# STM32N657xx register map
File version: 1.0
Registers are 32-bit, read-write, reset 0x0 unless marked. A register's access mark holds for its fields unless they carry their own. Offsets are from the block's base; [hi:lo] are bit positions; 'fields as' and 'values as' point back to an identical list; <NAME> marks a mode.

## LTDC — LCD-TFT Display Controller (LTDC)
Base 0x48001000
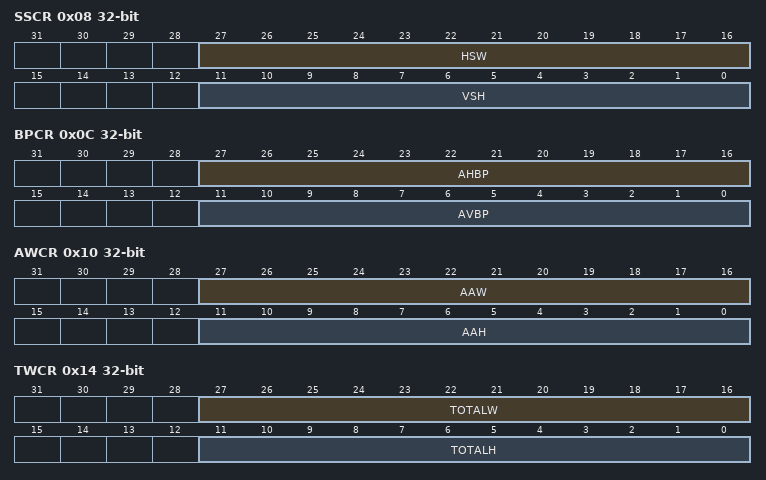
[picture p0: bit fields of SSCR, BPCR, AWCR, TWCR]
0x08 SSCR — LTDC synchronization size configuration register
  [27:16] HSW — horizontal synchronization width (in units of pixel clock period)These bits define the number of Horizontal Synchronization pixel minus 1
  [11:0] VSH — vertical synchronization height (in units of horizontal scan line)These bits define the vertical Synchronization height minus 1. It represents the number of horizontal synchronization lines
0x0C BPCR — LTDC back porch configuration register
  [27:16] AHBP — accumulated horizontal back porch (in units of pixel clock period)These bits define the accumulated horizontal back porch width that includes the horizontal synchronization and horizontal back porch pixels minus 1.The horizontal back porch is the period between horizontal synchronization going inactive and the start of the active display part of the next scan line
  [11:0] AVBP — accumulated Vertical back porch (in units of horizontal scan line)These bits define the accumulated vertical back porch width that includes the vertical synchronization and vertical back porch lines minus 1.The vertical back porch is the number of horizontal scan lines at a start of frame to the start of the first active scan line of the next frame
0x10 AWCR — LTDC active width configuration register
  [27:16] AAW — accumulated active width (in units of pixel clock period)These bits define the accumulated active width which includes the horizontal synchronization, horizontal back porch and active pixels minus 1.The active width is the number of pixels in active display area of the panel scan line.Refer to device datasheet for maximum active width supported following maximum pixel clock
  [11:0] AAH — accumulated active height (in units of horizontal scan line)These bits define the accumulated height which includes the vertical synchronization, vertical back porch and the active height lines minus 1. The active height is the number of active lines in the panel.Refer to device datasheet for maximum active height supported following maximum pixel clock
0x14 TWCR — LTDC total width configuration register
  [27:16] TOTALW — total width (in units of pixel clock period)These bits defines the accumulated total width which includes the horizontal synchronization, horizontal back porch, active width and horizontal front porch pixels minus 1
  [11:0] TOTALH — total height (in units of horizontal scan line)These bits defines the accumulated height which includes the vertical synchronization, vertical back porch, the active height and vertical front porch height lines minus 1
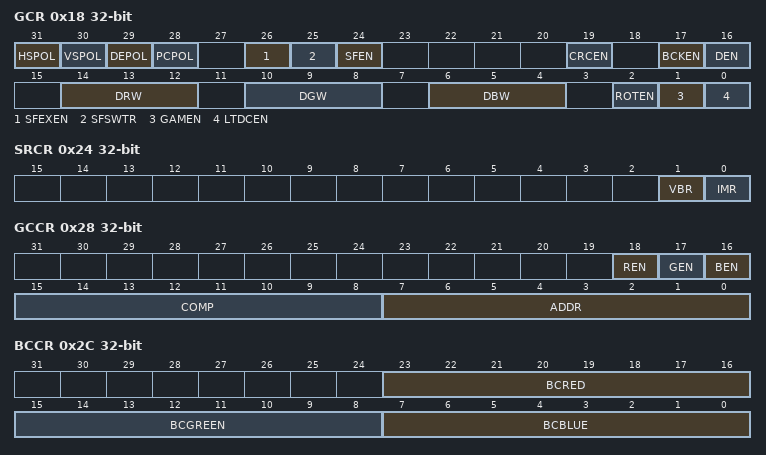
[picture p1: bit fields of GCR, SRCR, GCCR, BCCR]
0x18 GCR — LTDC global control register
  [31] HSPOL — horizontal synchronization polarityThis bit is set and cleared by software.- 0: horizontal synchronization polarity is active low.- 1: horizontal synchronization polarity is active high
  [30] VSPOL — vertical synchronization polarityThis bit is set and cleared by software.- 0: vertical synchronization is active low.- 1: vertical synchronization is active high
  [29] DEPOL — blanking (=no data/pixel) polarityThis bit is set and cleared by software.- 0: blanking (no data/pixel) polarity is active low.- 1: blanking (no data/pixel) polarity is active high
  [28] PCPOL — pixel clock polarityThis bit is set and cleared by software.- 0: pixel clock polarity is active low.- 1: pixel clock is active high
  [26] SFEXEN — single-frame mode: external trigger enableThis bit is set and cleared by software.- 0: external trigger disable- 1: external trigger enable: a trigger on the external trigger will generate one single frame
  [25] SFSWTR — single-frame mode: software triggerThis bit is set by software and cleared by hardware.- 0: no action- 1: triggers one frame
  [24] SFEN — single-frame mode: mode enableThis bit is set and cleared by software.- 0: single-frame disable:a trigger (on SFSW or External) will generate a continuous flow.- 1: single-frame enable: a trigger (on SFSW or External) will generate a single frame
  [19] CRCEN — CRC enableThis bit is set and cleared by software.- 0: CRC disable- 1: CRC enable
  [17] BCKEN — backgroundlayer enableThis bit is set and cleared by software.- 0: backgrounddisable- 1: background enable
  [16] DEN — dither enableThis bit is set and cleared by software.- 0: dither disable- 1: dither enable
  [14:12] DRW — dither red widthThese bits return the Dither Red Bits
  [10:8] DGW — dither green widthThese bits return the dither green bits
  [6:4] DBW — dither blue widthThese bits return the dither blue bits
  [2] ROTEN — LCD-TFT controller enableThis bit is set and cleared by software.- 0: Rotation disable- 1: Rotation enable (for a pure visual rotation, the mirroring has to be activated)
  [1] GAMEN — LCD-TFT controller enableThis bit is set and cleared by software.- 0: GammaCorrection disable (pixels bypass the gamma operator)- 1: Gamma Correction enable
  [0] LTDCEN — LCD-TFT controller enableThis bit is set and cleared by software.- 0: LTDC disable- 1: LTDC enable
0x24 SRCR — LTDC shadow reload configuration register
  [1] VBR — vertical blanking reload requestThis bit is set by software and cleared only by hardware after reload (it cannot be cleared through register write once it is set).- 0: no effect- 1: The shadow registers are reloaded during the vertical blanking period (at the beginning of the first line after the active display area)
  [0] IMR — immediate reload triggerThis bit is set by software and cleared only by hardware after reload.- 0: no effect- 1: The shadow registers are reloaded immediately
0x28 GCCR — LTDC gamma correction configuration register
  [18] REN — write trigger to the red table- 0: no action done- 1: COMP is written at ADDR in the Red table
  [17] GEN — write trigger to the green table- 0: no action done- 1: COMP is written at ADDR in the Green table
  [16] BEN — write trigger to the blue table- 0: no action done- 1: COMP is written at ADDR in the Blue table
  [15:8] COMP — color component to be written, in either (or all) the R,G,B tables
  [7:0] ADDR — address of the R,G,B table where the COMP component is written.When LTDC_GC1R.GCT=2, the gamma is implemented with 8 interpolated segment. In that case, the valid ADDR addresses are: 0, 32, 64, 96, 128, 160, 192, 224, 255.Note that for ADDR=255, the gamma interpolation hardware considers that the address is 256
0x2C BCCR — LTDC background color configuration register
  [23:16] BCRED — background color red valueThese bits configure the background red value
  [15:8] BCGREEN — background color green valueThese bits configure the background green value
  [7:0] BCBLUE — background color blue valueThese bits configure the background blue value
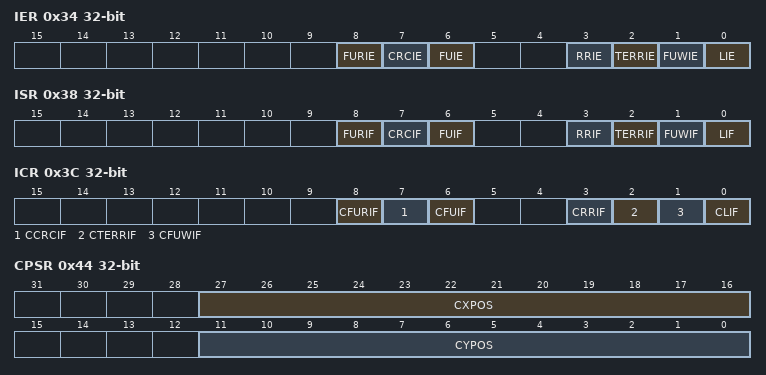
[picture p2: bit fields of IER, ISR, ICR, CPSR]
0x34 IER — LTDC interrupt enable register
  [8] FURIE — FIFOunderrun at rotation interrupt enableThis bit is set and cleared by software.- 0: FIFOunderrun at rotation interrupt disable- 1: FIFO underrunat rotation interrupt enable
  [7] CRCIE — CRC error interrupt enableThis bit is set and cleared by software.- 0: crcerror disable- 1: crc error interrupt enable
  [6] FUIE — FIFO underrun interrupt enableThis bit is set and cleared by software.- 0: FIFO underrun killing interrupt disable- 1: FIFO underrun killing Interrupt enable
  [3] RRIE — register reload interrupt enableThis bit is set and cleared by software.- 0: register reload interrupt disable- 1: register reload interrupt enable
  [2] TERRIE — transfer error interrupt enableThis bit is set and cleared by software.- 0: transfer error interrupt disable- 1: transfer error interrupt enable
  [1] FUWIE — FIFO underrun warning interrupt enableThis bit is set and cleared by software.- 0: FIFO underrun interrupt disable- 1: FIFO underrun Interrupt enable
  [0] LIE — line interrupt enableThis bit is set and cleared by software.- 0: line interrupt disable- 1: line interrupt enable
0x38 ISR — LTDC interrupt status register
  [8] FURIF — FIFO underrun at rotation interrupt flag- 0: no FIFO underrun at rotation interrupt generated- 1: FIFO underrun at rotation interrupt generated
  [7] CRCIF — transfer error interrupt flag- 0: no CRC error interrupt generated- 1: CRC error interrupt generated when the computed CRC is different from the expected CRC
  [6] FUIF — FIFO underrun interrupt flag- 0: no FIFO underrun killing interrupt generated.- 1: FIFO underrun killing interrupt generated, if one of the layer FIFOs is empty and many pixel data is read from the FIFO
  [3] RRIF — register reload interrupt flag- 0: no register reload interrupt generated- 1: register reload interrupt generated when a vertical blanking reload occurs (and the first line after the active area is reached)
  [2] TERRIF — transfer error interrupt flag- 0: no transfer error interrupt generated- 1: transfer error interrupt generated when a bus error occurs
  [1] FUWIF — FIFO underrun warning interrupt flag- 0: no FIFO underrun warning interrupt generated.- 1: FIFO underrun warning interrupt generated, if one of the layer FIFOs is empty and pixel data is read from the FIFO
  [0] LIF — line interrupt flag- 0: no line interrupt generated- 1: line interrupt generated when a programmed line is reached
0x3C ICR — LTDC Interrupt Clear Register
  [8] CFURIF — clears register reload interrupt flag- 0: no effect- 1: clears the FURIF flag in the LTDC_ISR register
  [7] CCRCIF — clears the transfer error interrupt flag- 0: no effect- 1: clears the CRCIF flag in the LTDC_ISR register
  [6] CFUIF — clears the FIFO underrun warning interrupt flag- 0: no effect- 1: clears the FUKIF flag in the LTDC_ISR register
  [3] CRRIF — clears register reload interrupt flag- 0: no effect- 1: clears the RRIF flag in the LTDC_ISR register
  [2] CTERRIF — clears the transfer error interrupt flag- 0: no effect- 1: clears the TERRIF flag in the LTDC_ISR register
  [1] CFUWIF — clears the FIFO underrun warning interrupt flag- 0: no effect- 1: clears the FUWIF flag in the LTDC_ISR register
  [0] CLIF — clears the line interrupt flag- 0: no effect- 1: clears the LIF flag in the LTDC_ISR register
0x40 LIPCR — LTDC line interrupt position configuration register
  [11:0] LIPOS — line interrupt positionThese bits configure the line interrupt position
0x44 CPSR — LTDC current position status register
  [27:16] CXPOS — current X positionThese bits return the current X position
  [11:0] CYPOS — current Y positionThese bits return the current Y position
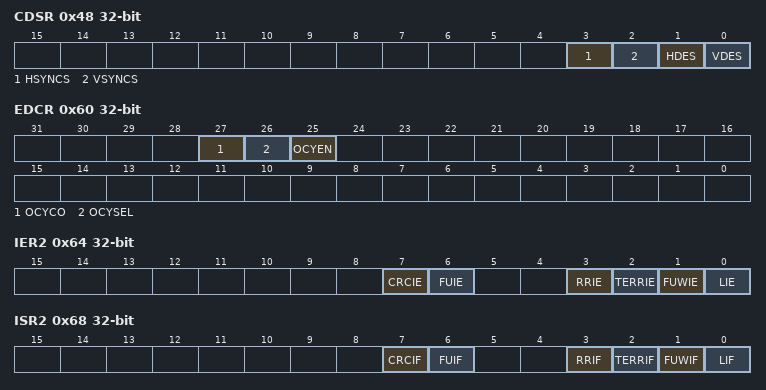
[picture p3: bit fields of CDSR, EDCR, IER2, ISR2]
0x48 CDSR — LTDC current display status register
  [3] HSYNCS — horizontal synchronization display status- 0: active low- 1: active high
  [2] VSYNCS — vertical synchronization display status- 0: active low- 1: active high
  [1] HDES — horizontal data enable display status- 0: active low- 1: active high
  [0] VDES — vertical data enable display status- 0: active low- 1: active high
0x60 EDCR — LTDC external display control register
  [27] OCYCO — output conversion to YCbCr 422: chrominance order.- 0: Cb is output first (so: Y0Cb, then Y1Cr, Y2Cb, etc .. ).- 1: Cr is output first (so: Y0Cr, then Y1Cb, Y2Cr, etc ..)
  [26] OCYSEL — output conversion to YCbCr 422: selection of the CCIR hard-wired coefficients:- 0: use CCIR-BT601 set (for typically SDTV analog-like displays)- 1: use CCIR-BT709 set (for typically HDTV digital-like displays)
  [25] OCYEN — output conversion to YCbCr 422: Enable- 0: conversion is disabled- 1: conversion is enabled
0x64 IER2 — LTDC interrupt enable register 2
  [7] CRCIE — CRC error interrupt enableThis bit is set and cleared by software.- 0: crcerror disable- 1: crc error interrupt enable
  [6] FUIE — FIFO underrun interrupt enableThis bit is set and cleared by software.- 0: FIFO underrun killing interrupt disable- 1: FIFO underrun killing Interrupt enable
  [3] RRIE — register reload interrupt enableThis bit is set and cleared by software.- 0: register reload interrupt disable- 1: register reload interrupt enable
  [2] TERRIE — transfer error interrupt enableThis bit is set and cleared by software.- 0: transfer error interrupt disable- 1: transfer error interrupt enable
  [1] FUWIE — FIFO underrun warning interrupt enableThis bit is set and cleared by software.- 0: FIFO underrun interrupt disable- 1: FIFO underrun Interrupt enable
  [0] LIE — line interrupt enableThis bit is set and cleared by software.- 0: line interrupt disable- 1: line interrupt enable
0x68 ISR2 — LTDC interrupt status register 2
  [7] CRCIF — transfer error interrupt flag- 0: no CRC error interrupt generated- 1: CRC error interrupt generated when a bus error occurs
  [6] FUIF — FIFO underrun interrupt flag- 0: no FIFO underrun killing interrupt generated.- 1: FIFO underrun killing interrupt generated, if one of the layer FIFOs is empty and many pixel data are read from the FIFO
  [3] RRIF — register reload interrupt flag- 0: no register reload interrupt generated- 1: register reload interrupt generated when a vertical blanking reload occurs (and the first line after the active area is reached)
  [2] TERRIF — transfer error interrupt flag- 0: no transfer error interrupt generated- 1: transfer error interrupt generated when a bus error occurs
  [1] FUWIF — FIFO underrun warning interrupt flag- 0: no FIFO underrun warning interrupt generated.- 1: FIFO underrun warning interrupt generated, if one of the layer FIFOs is empty and pixel data is read from the FIFO
  [0] LIF — line interrupt flag- 0: no line interrupt generated- 1: line interrupt generated when a programmed line is reached
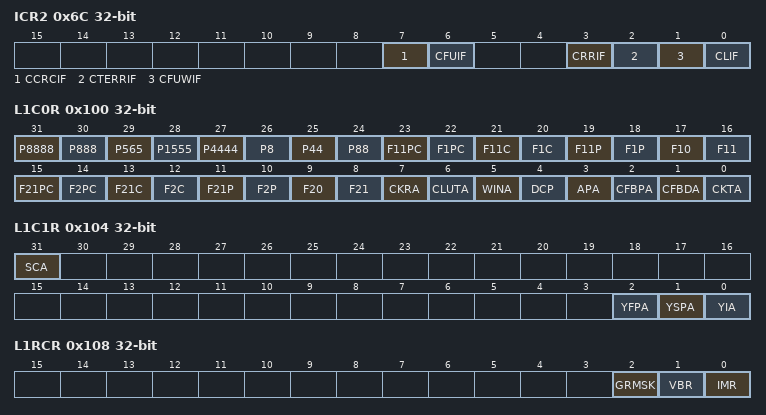
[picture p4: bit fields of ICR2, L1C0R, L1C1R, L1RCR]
0x6C ICR2 — LTDC Interrupt Clear Register 2
  [7] CCRCIF — clears the transfer error interrupt flag- 0: no effect- 1: clears the CRCIF flag in the LTDC_ISR register
  [6] CFUIF — clears the FIFO underrun warning interrupt flag- 0: no effect- 1: clears the FUKIF flag in the LTDC_ISR register
  [3] CRRIF — clears register reload interrupt flag- 0: no effect- 1: clears the RRIF flag in the LTDC_ISR register
  [2] CTERRIF — clears the transfer error interrupt flag- 0: no effect- 1: clears the TERRIF flag in the LTDC_ISR register
  [1] CFUWIF — clears the FIFO underrun warning interrupt flag- 0: no effect- 1: clears the FUWIF flag in the LTDC_ISR register
  [0] CLIF — clears the line interrupt flag- 0: no effect- 1: clears the LIF flag in the LTDC_ISR register
0x70 LIPCR2 — LTDC line interrupt position configuration register 2
  [15:0] LIPOS — line interrupt positionThese bits configure the line interrupt position
0x78 ECRCR — LTDC expected CRC register
  [15:0] ECRC — expected CRC of frame
0x7C CCRCR — LTDC computed CRC register
  [15:0] CCRC — expected CRC of frame
0x80 RB0AR — LTDC rotation buffer 0 address register
0x84 RB1AR — LTDC rotation buffer 1 address register
0x88 RBPR — LTDC rotation buffer pitch register
0x8C RIFCR — LTDC rotation intermediate frame color register
0x90 FUTR — LTDC FIFO underrun threshold register
  [15:0] THRE — threshold to trigger a FIFO underrun killing interrupt (unit is per fifo word, 64bit)
0x100 L1C0R — LTDC layer x configuration 0 register
  [31] P8888 — pixel format, ability for: ARGB8888
  [30] P888 — pixel format, ability for: RGB888
  [29] P565 — pixel format, ability for: RGB565
  [28] P1555 — pixel format, ability for: ARGB1555
  [27] P4444 — pixel format, ability for: ARGB4444
  [26] P8 — pixel format, ability for: L8
  [25] P44 — pixel format, ability for: AL44
  [24] P88 — pixel format, ability for: AL88
  [23] F11PC — blending factor 1, ability for: 1.0 - (pixel_alpha constant_alpha)
  [22] F1PC — blending factor 1, ability for: pixel_alpha constant_alpha
  [21] F11C — blending factor 1, ability for: 1.0 - constant_alpha
  [20] F1C — blending factor 1, ability for: constant_alpha
  [19] F11P — blending factor 1, ability for: 1.0 - pixel_alpha
  [18] F1P — blending factor 1, ability for: pixel_alpha
  [17] F10 — blending factor 1,ability for: 0.0
  [16] F11 — blending factor 1, ability for: 1.0
  [15] F21PC — blending factor 2, ability for: 1.0 - (pixel_alpha constant_alpha)
  [14] F2PC — blending factor 2, ability for: pixel_alpha constant_alpha
  [13] F21C — blending factor 2, ability for: 1.0 - constant_alpha
  [12] F2C — blending factor 2, ability for: constant_alpha
  [11] F21P — blending factor 2, ability for: 1.0 - pixel_alpha
  [10] F2P — blending factor 2, ability for: pixel_alpha
  [9] F20 — blending factor 2, ability for: 0.0
  [8] F21 — blending factor 2, ability for: 1.0
  [7] CKRA — color key replace ability
  [6] CLUTA — CLUT ability
  [5] WINA — windowing ability
  [4] DCP — default color programmability
  [3] APA — alpha plane ability
  [2] CFBPA — color frame buffer pitch ability
  [1] CFBDA — color frame buffer duplication ability
  [0] CKTA — color key transparency Ability
0x104 L1C1R — LTDC layer x configuration 1 register
  [31] SCA — scaling ability for that layer.- 0: scaling not available- 1: scaling available
  [2] YFPA — YCbCr 420 full-planar ability for that layer.- 0: full planar not available- 1: full planar available
  [1] YSPA — YCbCr 420 semi-planar ability for that layer.- 0: semiplanar not available- 1: semi-planar available
  [0] YIA — YCbCr 422 interleaved ability for that layer.- 0: interleaved not available- 1: interleaved available
0x108 L1RCR — LTDC layer x reload control register
  [2] GRMSK — shadow reload control: global (centralized) reload maskedThis bit is set and cleared by software.- 0: global reload active (the control from the LTDC_SRCR are enabled)- 1: global reload is masked (the control from the LTDC_SRCR are disabled)
  [1] VBR — vertical blanking reload requestThis bit is set by software and cleared only by hardware after reload (it cannot be cleared through register write once it is set).- 0: no effect- 1: The shadow registers are reloaded during the vertical blanking period (at the beginning of the first line after the active display area)
  [0] IMR — immediate reload triggerThis bit is set by software and cleared only by hardware after reload.- 0: no effect- 1: The shadow registers are reloaded immediately
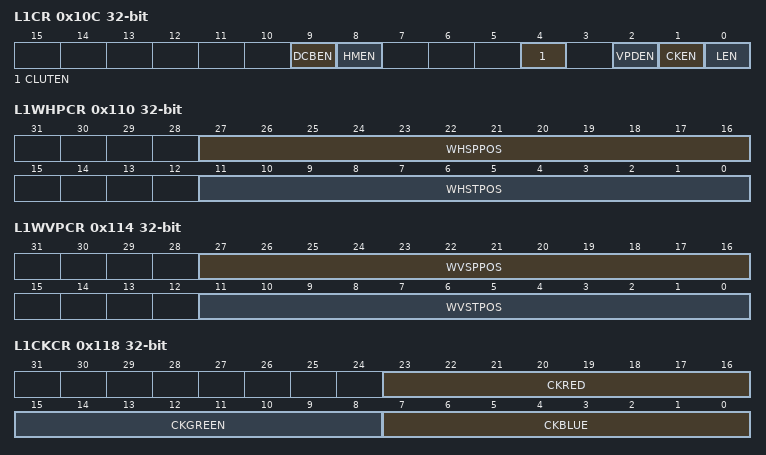
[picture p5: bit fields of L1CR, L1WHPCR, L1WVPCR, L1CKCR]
0x10C L1CR — LTDC layer x control register
  [9] DCBEN — default color blending enableThis bit is set and cleared by software.- 0: blending disabled- 1: blending enabled
  [8] HMEN — horizontal mirroring enableThis bit is set and cleared by software.- 0: mirror disabled- 1: mirror enabled (if so, the color frame buffer start address has to be set to the last byte of the first line, so for instannce: if line is 100 pixels, 24bpp, then address is set to 299)
  [4] CLUTEN — color look-up table enableThis bit is set and cleared by software.- 0: color look-up table disabled- 1: color look-up table enabledThe CLUT is only meaningful for L8, AL44 and AL88 pixel format. Refer to Color look-up table (CLUT)
  [2] VPDEN — vertical pixel duplication enableThis bit is set and cleared by software.- 0: duplication disabled- 1: duplication enabled
  [1] CKEN — color keying enableThis bit is set and cleared by software.- 0: color keying disabled- 1: color keying enabled: if RGB matches, then the ARGB are set to 0
  [0] LEN — layer enable: the bit is used to enable/disable the presence of this whole layer.This bit is set and cleared by software.- 0: layer disabled- 1: layer enabled
0x110 L1WHPCR — LTDC layer x window horizontal position configuration register
  [27:16] WHSPPOS — window horizontal stop positionThese bits configure the last visible pixel of a line of the layer window.WHSPPOS[15:0] must be <= AHBP[15:0] bits + 1 (programmed in LTDC_BPCR register)
  [11:0] WHSTPOS — window horizontal start positionThese bits configure the first visible pixel of a line of the layer window.WHSTPOS[15:0] must be >= AAW[15:0] bits (programmed in LTDC_AWCR register)
0x114 L1WVPCR — LTDC layer x window vertical position configuration register
  [27:16] WVSPPOS — window vertical stop positionThese bits configure the last visible line of the layer window.WVSPPOS[11:0] must be <= AVBP[15:0] bits + 1 (programmed in LTDC_BPCR register)
  [11:0] WVSTPOS — window vertical start positionThese bits configure the first visible line of the layer window.WVSTPOS[15:0] must be >= AAH[15:0] bits (programmed in LTDC_AWCR register)
0x118 L1CKCR — LTDC layer x color keying configuration register
  [23:16] CKRED — color key red value
  [15:8] CKGREEN — color key green value
  [7:0] CKBLUE — color key blue value
0x11C L1PFCR — LTDC layer x pixel format configuration register
  [2:0] PF — pixel formatThese bits configure the pixel format- 000: ARGB8888- 001: RGB888- 010: RGB565- 011: ARGB1555- 100: ARGB4444- 101: L8 (8-bit luminance)- 110: AL44 (4-bit alpha, 4-bit luminance)- 111: AL88 (8-bit alpha, 8-bit luminance)
0x120 L1CACR — LTDC layer x constant alpha configuration register
  [7:0] CONSTA — constant alphaThese bits configure the constant alpha used for blending. The constant alpha is divided by 255 by hardware.Example: if the programmed constant alpha is 0xFF, the constant alpha value is 255 / 255 = 1
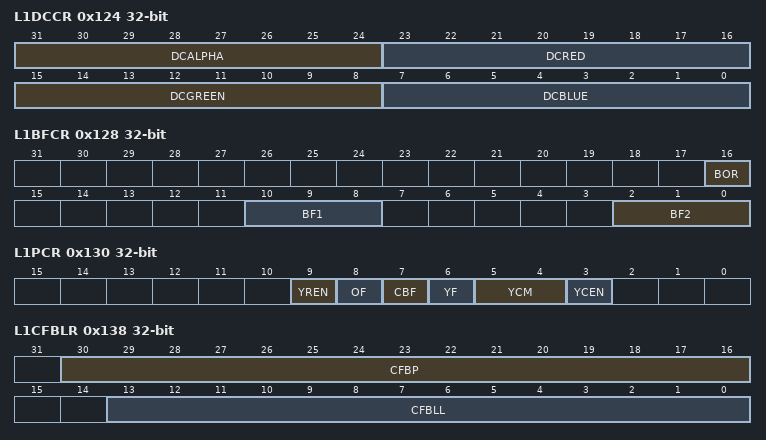
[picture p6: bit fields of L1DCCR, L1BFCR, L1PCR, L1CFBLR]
0x124 L1DCCR — LTDC layer x default color configuration register
  [31:24] DCALPHA — default color alphaThese bits configure the default alpha value
  [23:16] DCRED — default color redThese bits configure the default red value
  [15:8] DCGREEN — default color greenThese bits configure the default green value
  [7:0] DCBLUE — default color blueThese bits configure the default blue value
0x128 L1BFCR — LTDC layer x blending factors configuration register
  [16] BOR — blending orderThese bits select the blending orderBOR.BOR= 0000 is for the most background layer (usually hidden behind others)BOR= 1111 is for the most foreground layer (always visible, never hidden by any other).In case of inconsistency, like two layers at same order, the blending engine reverses to BOR[LayerID] = LayerID-1, so that Layer3 is in foreground and Layer1 is in background.Note: if the Layer3 is set as secure, to guarantee it is on the foreground, it should be configured with BOR(Layer3)=1111
  [10:8] BF1 — blending factor 1These bits select the blending factor F1.- 000: reserved- 001: reserved- 010: reserved- 011: reserved- 100: constant alpha- 101: reserved- 110: pixel alpha x constant alpha- 111: reserved
  [2:0] BF2 — blending factor 2These bits select the blending factor F2- 000: reserved- 001: reserved- 010: reserved- 011: reserved- 100: reserved- 101: 1 - constant alpha- 110: reserved- 111: 1 - (pixel alpha x constant alpha)
0x12C L1BLCR — LTDC layer x burst length configuration register
  [4:0] BL — burst length- 0x00: maximum burst length (16 words 64bit, thus 128 Bytes)- 0x01: 1 word (of 64bit) per burst..- 0x10: 16 words (of 64bit) per burst- 0x11: reserved...- 0xFF: reserved
0x130 L1PCR — LTDC layer x planar configuration register
  [9] YREN — Y Rescale EnableWhen enabled, incoming Y values in range 16..235 are re-scaled to range 0..255, - 0: rescaling disabled.- 1: rescaling enabled
  [8] OF — Odd Pixel FirstDefines if the byte 0 of a word (in LSB) contains the Odd pixel.- 0: odd pixel disabled (thus even pixel on byte 0)- 1: odd pixel enabled (thus odd pixel on byte 0)
  [7] CBF — Cb Component FirstDefines if the byte 0 and 1 of a word (in LSB) contains the Cb component. The setting impacts only for interleaved and semi-planar modes, as it has no meaning in full-planar mode)- 0: Cb disabled (thus Cr component is on byte 0 and 1)- 1: Cb enabled (thus Cb component is on byte 0 and 1)
  [6] YF — Y Component FirstDefines if the byte 0 of a word (in LSB) contains the Y component.- 0: Y component disabled (thus Cr or Cb component is on byte 0)- 1: Y component enabled (thus Y component is on byte 0)
  [5:4] YCM — YCbCr Conversion ModeDefined the type of input that is considered and converted to a YCbCr 444:- 00: interleaved 422 (Cb and Cr component are replicated horizontally for pixels P and P+1)- 01: semi-Planar 420: (Cb and Cr component are replicated horizontally and vertically. The layer main configuration defines the access to the Y buffer, and auxiliary registers define the access to the Cb and Cr buffers).- 10: full-Planar 420: (Cb and Cr component are replicated horizontally and vertically. The layer main configuration defines the access to the Y buffer, and auxiliary registers define the access to the Cb and Cr buffers).- 11: reserved
  [3] YCEN — YCbCr-to-RGB Conversion Enable:- 0: conversion disabled.- 1: YCbCr conversion enabled, using the YCM setting above
0x134 L1CFBAR — LTDC layer x color frame buffer address register
  [31:0] CFBADD — color frame buffer start addressThese bits define the color frame buffer start address
0x138 L1CFBLR — LTDC layer x color frame buffer length register
  [30:16] CFBP — color frame buffer pitch in bytesThese bits define the pitch that is the increment from the start of one line of pixels to the start of the next line in bytes.Negative values (with msb bit = 1) are allowed, to read the buffer from bottom to top, and thus to flip is vertically. When vertically flipped, as the address register must provide the address of the first line to be read, the address register must point to the start of the bottom line of the buffer
  [13:0] CFBLL — color frame buffer line lengthThese bits define the length of one line of pixels in bytes + 7.The line length is computed as follows:active high width number of bytes per pixel + 7
0x13C L1CFBLNR — LTDC layer x color frame buffer line number register
  [11:0] CFBLNBR — frame buffer line numberThese bits define the number of lines in the frame buffer that corresponds to the active high width
0x140 AFBA0R1 — LTDC layer x auxiliary frame buffer address 0 register
0x144 AFBA1R1 — LTDC layer x auxiliary frame buffer address 1 register
0x148 AFBLR1 — LTDC layer x auxiliary frame buffer length register
0x14C AFBLNR1 — LTDC layer x auxiliary frame buffer line number register
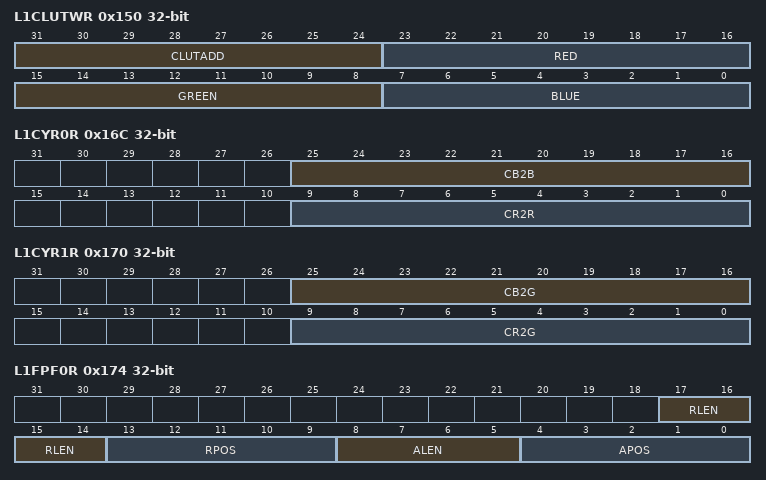
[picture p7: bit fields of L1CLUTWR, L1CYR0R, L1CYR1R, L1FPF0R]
0x150 L1CLUTWR — LTDC layer x CLUT write register
  [31:24] CLUTADD — CLUT addressThese bits configure the CLUT address (color position within the CLUT) of each RGB value
  [23:16] RED — red valueThese bits configure the red value
  [15:8] GREEN — green valueThese bits configure the green value
  [7:0] BLUE — blue valueThese bits configure the blue value
0x154 SISR1 — LTDC layer x Scaler Input Size register
0x158 SOSR1 — LTDC layer x Scaler Output Size register
0x15C SVSFR1 — LTDC layer x Scaler Vertical Scaling Factor register
0x160 SVSPR1 — LTDC layer x Scaler Vertical Scaling Phase register
0x164 SHSFR1 — LTDC layer x Scaler Horizontal Scaling Factor register
0x168 SHSPR1 — LTDC layer x Scaler Horizontal Scaling Phase register
0x16C L1CYR0R — LTDC layer x Conversion YCbCr RGB 0 register
  [25:16] CB2B — Cb-to-Blue coefficient, with bits 9:8 as positive integer and 7:0 as decimals
  [9:0] CR2R — Cr-to-Red coefficient, with bits 9:8 as positive integer and 7:0 as decimals
0x170 L1CYR1R — LTDC layer x Conversion YCbCr RGB 1 register
  [25:16] CB2G — Cb-to-Green coefficient, with bits 9:8 as positive integer and 7:0 as decimals
  [9:0] CR2G — Cr-to-Green coefficient, with bits 9:8 as positive integer and 7:0 as decimals
0x174 L1FPF0R — LTDC layer x Flexible Pixel Format 0 register
  [17:14] RLEN — Width of the red component (in bits)
  [13:9] RPOS — Location of the red component inside the pixel memory word (in bits)
  [8:5] ALEN — Width of the alpha component (in bits)
  [4:0] APOS — Location of the alpha component inside the pixel memory word (in bits)
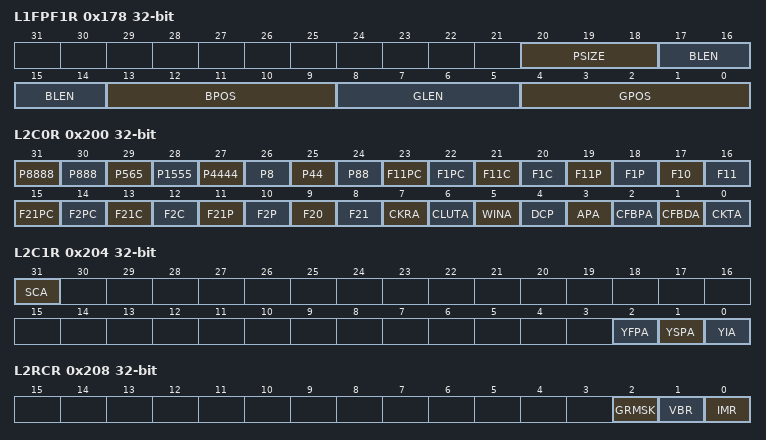
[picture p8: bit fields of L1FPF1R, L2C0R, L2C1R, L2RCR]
0x178 L1FPF1R — LTDC layer x Flexible Pixel Format 1 register
  [20:18] PSIZE — Width of the red component (in bits)
  [17:14] BLEN — Width of the red component (in bits)
  [13:9] BPOS — Location of the red component inside the pixel memory word (in bits)
  [8:5] GLEN — Width of the alpha component (in bits)
  [4:0] GPOS — Location of the alpha component inside the pixel memory word (in bits)
0x200 L2C0R — LTDC layer x configuration 0 register
  fields as L1C0R
0x204 L2C1R — LTDC layer x configuration 1 register
  fields as L1C1R
0x208 L2RCR — LTDC layer x reload control register
  fields as L1RCR
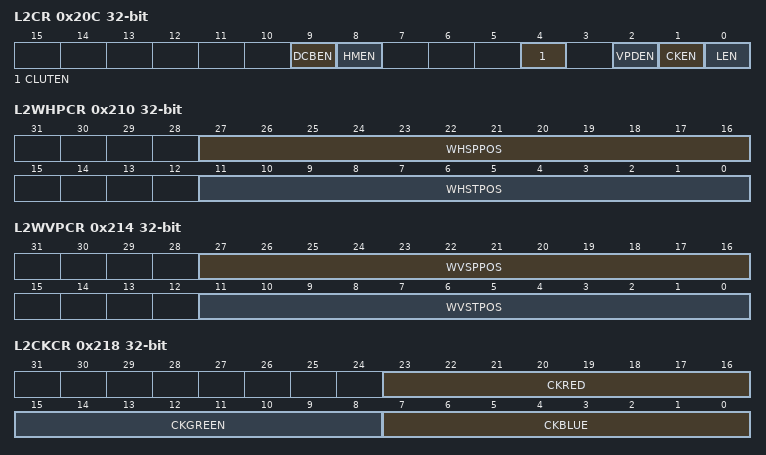
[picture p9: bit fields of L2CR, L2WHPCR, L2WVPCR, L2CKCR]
0x20C L2CR — LTDC layer x control register
  fields as L1CR
0x210 L2WHPCR — LTDC layer x window horizontal position configuration register
  fields as L1WHPCR
0x214 L2WVPCR — LTDC layer x window vertical position configuration register
  fields as L1WVPCR
0x218 L2CKCR — LTDC layer x color keying configuration register
  fields as L1CKCR
0x21C L2PFCR — LTDC layer x pixel format configuration register
  fields as L1PFCR
0x220 L2CACR — LTDC layer x constant alpha configuration register
  fields as L1CACR
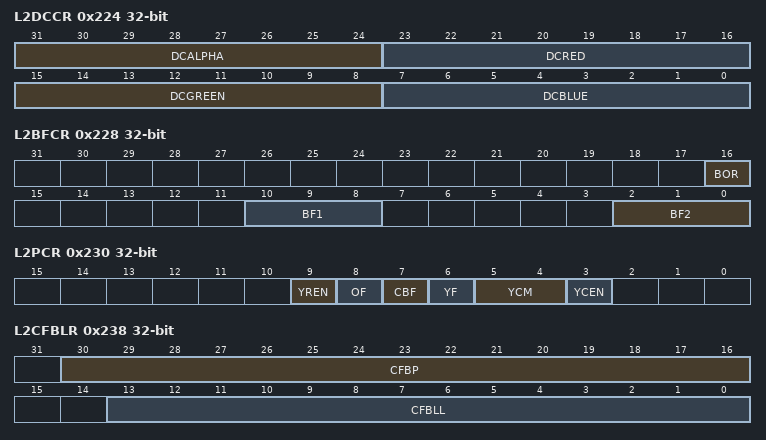
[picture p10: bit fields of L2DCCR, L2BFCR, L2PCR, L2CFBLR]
0x224 L2DCCR — LTDC layer x default color configuration register
  fields as L1DCCR
0x228 L2BFCR — LTDC layer x blending factors configuration register
  fields as L1BFCR
0x22C L2BLCR — LTDC layer x burst length configuration register
  fields as L1BLCR
0x230 L2PCR — LTDC layer x planar configuration register
  fields as L1PCR
0x234 L2CFBAR — LTDC layer x color frame buffer address register
  fields as L1CFBAR
0x238 L2CFBLR — LTDC layer x color frame buffer length register
  fields as L1CFBLR
0x23C L2CFBLNR — LTDC layer x color frame buffer line number register
  fields as L1CFBLNR
0x240 AFBA0R2 — LTDC layer x auxiliary frame buffer address 0 register
0x244 AFBA1R2 — LTDC layer x auxiliary frame buffer address 1 register
0x248 AFBLR2 — LTDC layer x auxiliary frame buffer length register
0x24C AFBLNR2 — LTDC layer x auxiliary frame buffer line number register
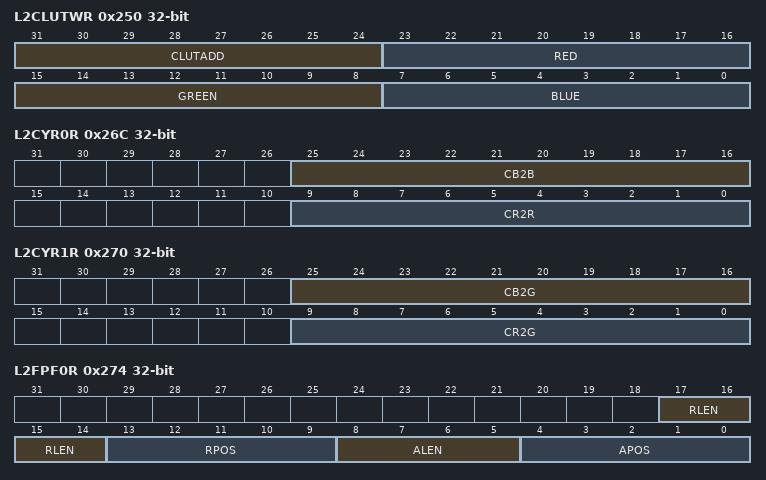
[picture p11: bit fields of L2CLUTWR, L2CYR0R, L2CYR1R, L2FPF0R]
0x250 L2CLUTWR — LTDC layer x CLUT write register
  fields as L1CLUTWR
0x254 SISR2 — LTDC layer x Scaler Input Size register
0x258 SOSR2 — LTDC layer x Scaler Output Size register
0x25C SVSFR2 — LTDC layer x Scaler Vertical Scaling Factor register
0x260 SVSPR2 — LTDC layer x Scaler Vertical Scaling Phase register
0x264 SHSFR2 — LTDC layer x Scaler Horizontal Scaling Factor register
0x268 SHSPR2 — LTDC layer x Scaler Horizontal Scaling Phase register
0x26C L2CYR0R — LTDC layer x Conversion YCbCr RGB 0 register
  fields as L1CYR0R
0x270 L2CYR1R — LTDC layer x Conversion YCbCr RGB 1 register
  fields as L1CYR1R
0x274 L2FPF0R — LTDC layer x Flexible Pixel Format 0 register
  fields as L1FPF0R
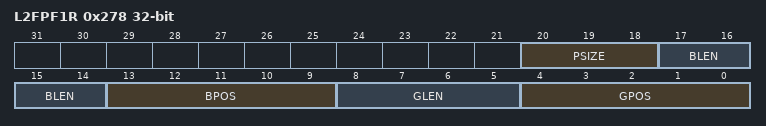
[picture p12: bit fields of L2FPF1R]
0x278 L2FPF1R — LTDC layer x Flexible Pixel Format 1 register
  fields as L1FPF1R
